# W806 register map
Vendor: Beijing Lianshengde Micro-electronics Co., Ltd.; File version: 1.0
W806 general purpose microcontroller
Registers are 32-bit, read-write, reset 0x0 unless marked. A register's access mark holds for its fields unless they carry their own. Offsets are from the block's base; lines under a group give offsets from that group; [hi:lo] are bit positions; {n}, {i} and the like mark numbered series; 'fields as' and 'values as' point back to an identical list; <NAME> marks a mode.

## Memory map
0x40000000 SPI — Serial peripheral interface
0x40000000 RSA — RSA Montgomery FIOS algorithm coprocessor
0x40000800 DMA — Direct memory access module
0x40000D00 PMU — Power management unit
0x40000E00 RCC — System clock and reset controller
0x40002000 FLASH — Internal flash controller
0x40010000 I2C — Inter-Integrated Circuit bus
0x40010200 ADC — Analog-digital converter
{0x40010600+0x200*n} UART[{n}] (n=0..5) — Universal asynchronous receiver/transmitter
0x40011200 GPIO[{x}] (x=A,B; step 0x200) — General purpose input/output module
0x40011600 WDOG — Watchdog module
0x40011800 TIMER — Timer counter module
0x40011E00 PWM — Pulse-width modulation module
0x40012400 TOUCH — Touchpad sensor module

## DMA — Direct memory access module
Base 0x40000800
Same registers: SPI 0x40000000, RSA 0x40000000, FLASH 0x40002000, I2C 0x40010000, ADC 0x40010200, WDOG 0x40011600, TIMER 0x40011800, PWM 0x40011E00, TOUCH 0x40012400
0x00 todo reset not defined — ??

## UART[{n}] — Universal asynchronous receiver/transmitter
Base 0x40010600; array of 6, step 0x200
Registers as DMA.

## PMU — Power management unit
Base 0x40000D00
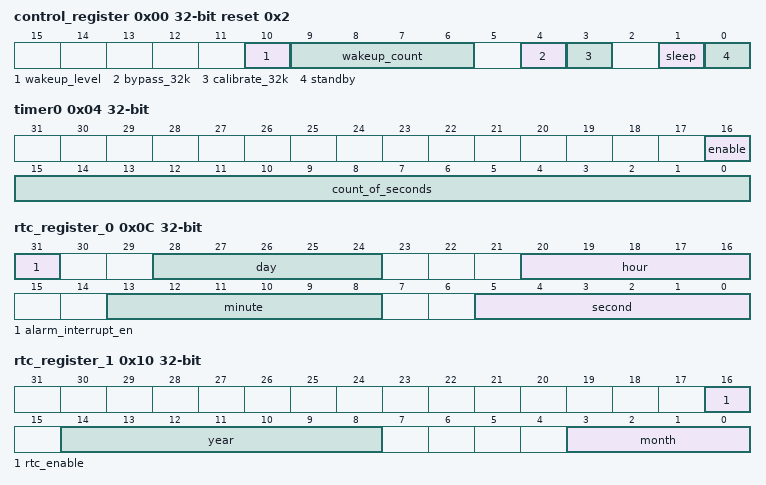
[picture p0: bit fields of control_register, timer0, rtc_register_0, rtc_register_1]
0x00 control_register reset 0x2 (reset mask 0x45B) — PMU control register
  [10] wakeup_level — IO wake-up polarity selection
    0=low (Low level interrupts); 1=High level interrupt
  [9:6] wakeup_count — IO wake-up Minimum hold count of 128ms
  [4] bypass_32k — Bypass 32k oscillator
    0=Disable bypass 32k oscillator; 1=Enable bypass 32k oscillator
  [3] calibrate_32k — Calibrate 32k oscillator
    0=off (Stop calibrate 32k oscillator); 1=on (Start up calibrate 32k oscillator)
  [1] sleep — Sleep enable
    0=Disable sleep; 1=Enable sleep
  [0] standby — Standby enable
    0=Disable standby; 1=Enable standby
0x04 timer0
  [16] enable — PMU timer0 enable
    0=Disable timer0; 1=Enable timer0
  [15:0] count_of_seconds — PMU timer0 initial count of seconds register
0x0C rtc_register_0
  [31] alarm_interrupt_en — Alarm interrupt enable
    0=disable (RTC does not generate Alarm Interrupts); 1=enable (RTC triggers the Alarm Interrupt)
  [28:24] day
  [20:16] hour
  [13:8] minute
  [5:0] second
0x10 rtc_register_1
  [16] rtc_enable
    0=disable (RTC disable); 1=enable (RTC enable)
  [14:8] year
  [3:0] month
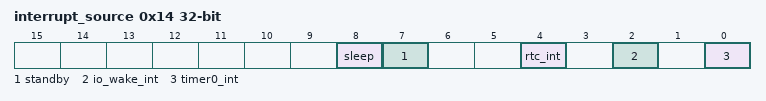
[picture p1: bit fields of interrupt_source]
0x14 interrupt_source — PMU interrupt source register
  [8] sleep — Whether power-on from sleep
    0=disappear wake up from sleep; 1=appear wake up from sleep, set clear
  [7] standby — Whether power-on from standby
    0=disappear wake up from standby; 1=appear wake up from standby, set clear
  [4] rtc_int — RTC interrupt flag
    0=no_interrupt (No RTC interrupt is generated.); 1=has_interrupt_set_clr (RTC interrupt is generated, set clear)
  [2] io_wake_int — IO wake up interrupt flag
    0=no_interrupt (No IO wake up interrupt is generated.); 1=has_interrupt_set_clr (IO wake up interrupt is generated, set clear)
  [0] timer0_int — PMU TIMER0 interrupt flag
    0=no_interrupt (No PMU TIMER0 interrupt is generated.); 1=has_interrupt_set_clr (PMU TIMER0 interrupt is generated, set clear)

## Licence text in the file
Copyright (c) 2021 Rustcc Embedded Wechat Group W806-SVD is licensed under Mulan PSL v2. You can use this software according to the terms and conditions of the Mulan PSL v2. You may obtain a copy of Mulan PSL v2 at: http://license.coscl.org.cn/MulanPSL2 THIS SOFTWARE IS PROVIDED ON AN "AS IS" BASIS, WITHOUT WARRANTIES OF ANY KIND, EITHER EXPRESS OR IMPLIED, INCLUDING BUT NOT LIMITED TO NON-INFRINGEMENT, MERCHANTABILITY OR FIT FOR A PARTICULAR PURPOSE. See the Mulan PSL v2 for more details.
